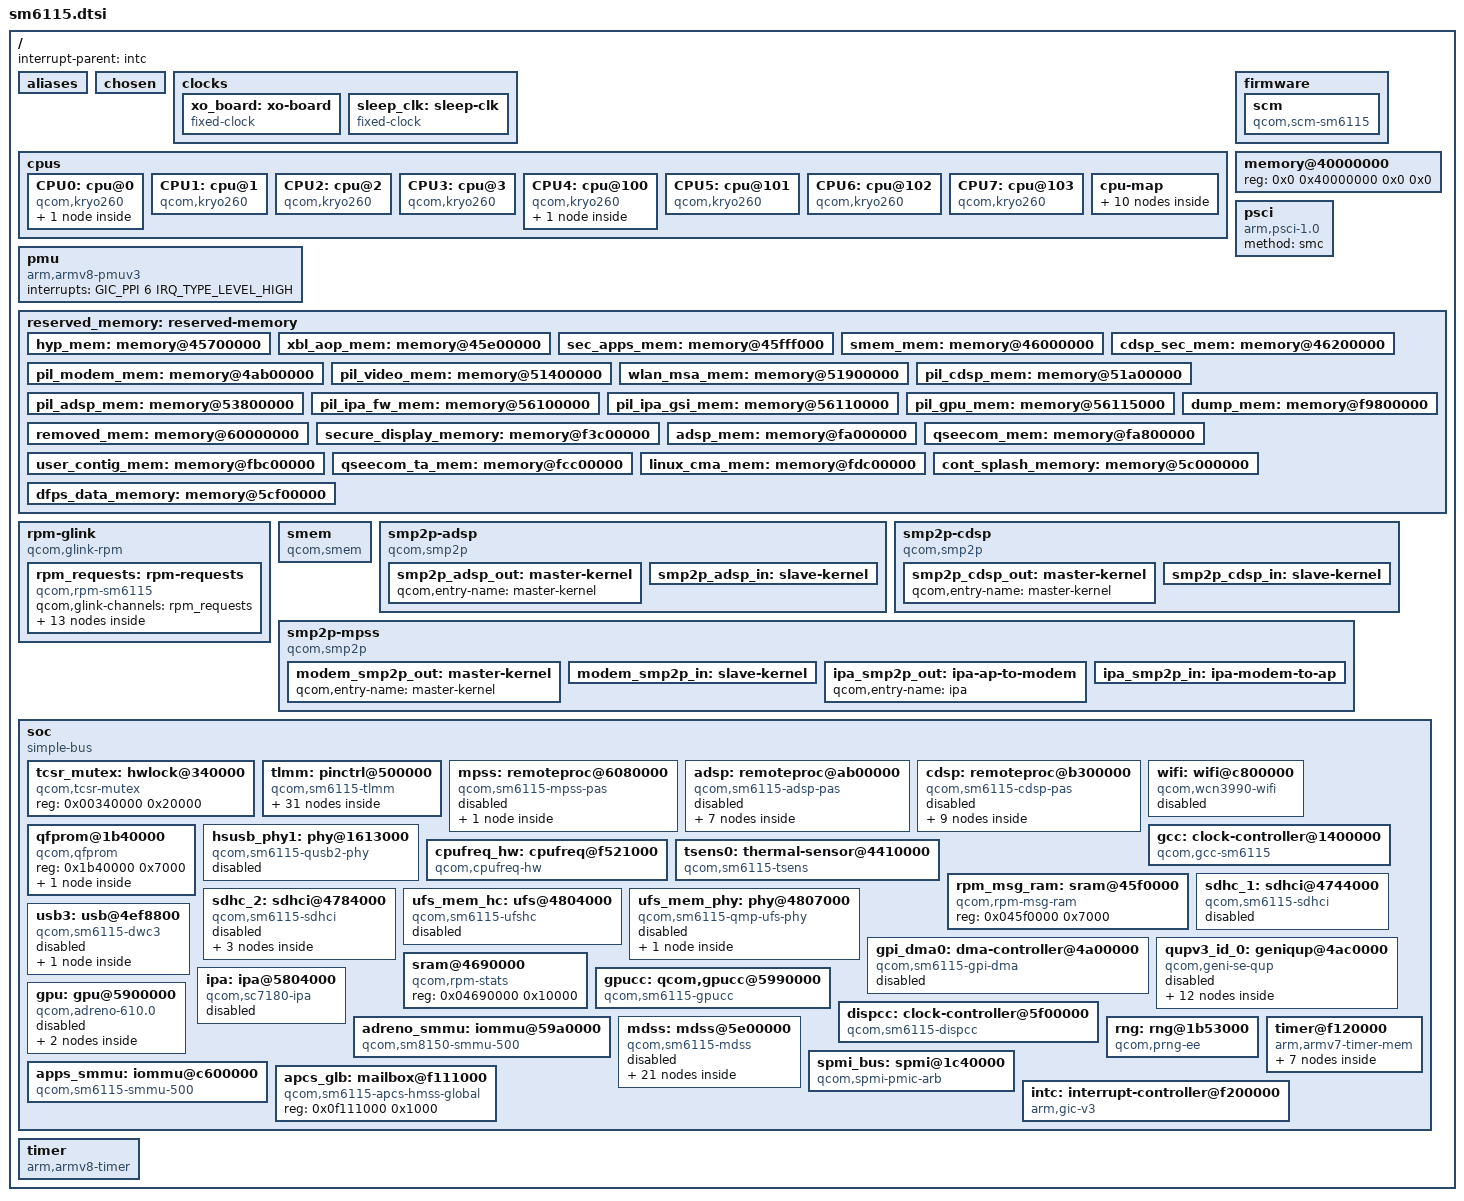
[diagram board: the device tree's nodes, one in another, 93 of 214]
// SPDX-License-Identifier: BSD-3-Clause

#include <dt-bindings/clock/qcom,gcc-sm6115.h>
#include <dt-bindings/clock/qcom,dispcc-sm6115.h>
#include <dt-bindings/clock/qcom,gpucc-sm6115.h>
#include <dt-bindings/clock/qcom,rpmcc.h>
#include <dt-bindings/gpio/gpio.h>
#include <dt-bindings/interrupt-controller/arm-gic.h>
#include <dt-bindings/power/qcom-rpmpd.h>

/ {
	interrupt-parent = <&intc>;
	#address-cells = <2>;
	#size-cells = <2>;
	
	aliases {
		
		mmc0 = &sdhc_1;
		mmc1 = &sdhc_2;
	};
	
	chosen {
		#address-cells = <2>;
		#size-cells = <2>;
		ranges;
		
	 };

	clocks {
		xo_board: xo-board {
			compatible = "fixed-clock";
			#clock-cells = <0>;
			clock-frequency = <19200000>;
			clock-output-names = "xo_board";
		};

		sleep_clk: sleep-clk {
			compatible = "fixed-clock";
			#clock-cells = <0>;
			clock-frequency = <32764>;
			clock-output-names = "sleep_clk";
		};
	};

	cpus {
		#address-cells = <2>;
		#size-cells = <0>;

		CPU0: cpu@0 {
			device_type = "cpu";
			compatible = "qcom,kryo260";
			reg = <0x0 0x0>;
			enable-method = "psci";
			capacity-dmips-mhz = <1024>;
			next-level-cache = <&L2_0>;
			qcom,freq-domain = <&cpufreq_hw 0>;
			L2_0: l2-cache {
				compatible = "cache";
			};
		};

		CPU1: cpu@1 {
			device_type = "cpu";
			compatible = "qcom,kryo260";
			reg = <0x0 0x1>;
			enable-method = "psci";
			capacity-dmips-mhz = <1024>;
			next-level-cache = <&L2_0>;
			qcom,freq-domain = <&cpufreq_hw 0>;
		};

		CPU2: cpu@2 {
			device_type = "cpu";
			compatible = "qcom,kryo260";
			reg = <0x0 0x2>;
			enable-method = "psci";
			capacity-dmips-mhz = <1024>;
			next-level-cache = <&L2_0>;
			qcom,freq-domain = <&cpufreq_hw 0>;
		};

		CPU3: cpu@3 {
			device_type = "cpu";
			compatible = "qcom,kryo260";
			reg = <0x0 0x3>;
			enable-method = "psci";
			capacity-dmips-mhz = <1024>;
			next-level-cache = <&L2_0>;
			qcom,freq-domain = <&cpufreq_hw 0>;
		};

		CPU4: cpu@100 {
			device_type = "cpu";
			compatible = "qcom,kryo260";
			reg = <0x0 0x100>;
			enable-method = "psci";
			capacity-dmips-mhz = <1638>;
			next-level-cache = <&L2_1>;
			qcom,freq-domain = <&cpufreq_hw 1>;
			L2_1: l2-cache {
				compatible = "cache";
			};
		};

		CPU5: cpu@101 {
			device_type = "cpu";
			compatible = "qcom,kryo260";
			reg = <0x0 0x101>;
			enable-method = "psci";
			capacity-dmips-mhz = <1638>;
			next-level-cache = <&L2_1>;
			qcom,freq-domain = <&cpufreq_hw 1>;
		};

		CPU6: cpu@102 {
			device_type = "cpu";
			compatible = "qcom,kryo260";
			reg = <0x0 0x102>;
			enable-method = "psci";
			capacity-dmips-mhz = <1638>;
			next-level-cache = <&L2_1>;
			qcom,freq-domain = <&cpufreq_hw 1>;
		};

		CPU7: cpu@103 {
			device_type = "cpu";
			compatible = "qcom,kryo260";
			reg = <0x0 0x103>;
			enable-method = "psci";
			capacity-dmips-mhz = <1638>;
			next-level-cache = <&L2_1>;
			qcom,freq-domain = <&cpufreq_hw 1>;
		};

		cpu-map {
			cluster0 {
				core0 {
					cpu = <&CPU0>;
				};

				core1 {
					cpu = <&CPU1>;
				};

				core2 {
					cpu = <&CPU2>;
				};

				core3 {
					cpu = <&CPU3>;
				};
			};

			cluster1 {
				core0 {
					cpu = <&CPU4>;
				};

				core1 {
					cpu = <&CPU5>;
				};

				core2 {
					cpu = <&CPU6>;
				};

				core3 {
					cpu = <&CPU7>;
				};
			};
		};
	};

	firmware {
		scm: scm {
			compatible = "qcom,scm-sm6115", "qcom,scm";
			#reset-cells = <1>;
		};
	};

	memory@40000000 {
		/* We expect the bootloader to fill in the size */
		reg = <0x0 0x40000000 0x0 0x0>;
		device_type = "memory";
	};

	pmu {
		compatible = "arm,armv8-pmuv3";
		interrupts = <GIC_PPI 6 IRQ_TYPE_LEVEL_HIGH>;
	};

	psci {
		compatible = "arm,psci-1.0";
		method = "smc";
	};

	reserved_memory: reserved-memory {
		#address-cells = <2>;
		#size-cells = <2>;
		ranges;

		hyp_mem: memory@45700000 {
			reg = <0x0 0x45700000 0x0 0x600000>;
			no-map;
		};

		xbl_aop_mem: memory@45e00000 {
			reg = <0x0 0x45e00000 0x0 0x140000>;
			no-map;
		};

		sec_apps_mem: memory@45fff000 {
			reg = <0x0 0x45fff000 0x0 0x1000>;
			no-map;
		};

		smem_mem: memory@46000000 {
			reg = <0x0 0x46000000 0x0 0x200000>;
			no-map;
		};

		cdsp_sec_mem: memory@46200000 {
			reg = <0x0 0x46200000 0x0 0x1e00000>;
			no-map;
		};

		pil_modem_mem: memory@4ab00000 {
			reg = <0x0 0x4ab00000 0x0 0x6900000>;
			no-map;
		};

		pil_video_mem: memory@51400000 {
			reg = <0x0 0x51400000 0x0 0x500000>;
			no-map;
		};

		wlan_msa_mem: memory@51900000 {
			reg = <0x0 0x51900000 0x0 0x100000>;
			no-map;
		};

		pil_cdsp_mem: memory@51a00000 {
			reg = <0x0 0x51a00000 0x0 0x1e00000>;
			no-map;
		};

		pil_adsp_mem: memory@53800000 {
			reg = <0x0 0x53800000 0x0 0x2800000>;
			no-map;
		};

		pil_ipa_fw_mem: memory@56100000 {
			reg = <0x0 0x56100000 0x0 0x10000>;
			no-map;
		};

		pil_ipa_gsi_mem: memory@56110000 {
			reg = <0x0 0x56110000 0x0 0x5000>;
			no-map;
		};

		pil_gpu_mem: memory@56115000 {
			reg = <0x0 0x56115000 0x0 0x2000>;
			no-map;
		};

		removed_mem: memory@60000000 {
			reg = <0x0 0x60000000 0x0 0x3900000>;
			no-map;
		};

		secure_display_memory: memory@f3c00000 {
			reg = <0x0 0xf3c00000 0x0 0x5c00000>;
			no-map;
		};

		dump_mem: memory@f9800000 {
			reg = <0x0 0xf9800000 0x0 0x800000>;
			no-map;
		};

		adsp_mem: memory@fa000000 {
			reg = <0x0 0xfa000000 0x0 0x800000>;
			no-map;
		};

		qseecom_mem: memory@fa800000 {
			reg = <0x0 0xfa800000 0x0 0x1400000>;
			no-map;
		};

		user_contig_mem: memory@fbc00000 {
			reg = <0x0 0xfbc00000 0x0 0x1000000>;
			no-map;
		};

		qseecom_ta_mem: memory@fcc00000 {
			reg = <0x0 0xfcc00000 0x0 0x1000000>;
			no-map;
		};

		linux_cma_mem: memory@fdc00000 {
			reg = <0x0 0xfdc00000 0x0 0x2000000>;
			no-map;
		};

		cont_splash_memory: memory@5c000000 {
			reg = <0x0 0x5c000000 0x0 0x00f00000>;
			no-map;
		};

		dfps_data_memory: memory@5cf00000 {
			reg = <0x0 0x5cf00000 0x0 0x0100000>;
			no-map;
		};

	};

	rpm-glink {
		compatible = "qcom,glink-rpm";

		interrupts = <GIC_SPI 194 IRQ_TYPE_EDGE_RISING>;
		qcom,rpm-msg-ram = <&rpm_msg_ram>;
		mboxes = <&apcs_glb 0>;

		rpm_requests: rpm-requests {
			compatible = "qcom,rpm-sm6115";
			qcom,glink-channels = "rpm_requests";

			rpmcc: clock-controller {
				compatible = "qcom,rpmcc-sm6115", "qcom,rpmcc";
				#clock-cells = <1>;
			};

			rpmpd: power-controller {
				compatible = "qcom,sm6115-rpmpd";
				#power-domain-cells = <1>;
				operating-points-v2 = <&rpmpd_opp_table>;

				rpmpd_opp_table: opp-table {
					compatible = "operating-points-v2";

					rpmpd_opp_ret: opp1 {
						opp-level = <RPM_SMD_LEVEL_RETENTION>;
					};

					rpmpd_opp_ret_plus: opp2 {
						opp-level = <RPM_SMD_LEVEL_RETENTION_PLUS>;
					};

					rpmpd_opp_min_svs: opp3 {
						opp-level = <RPM_SMD_LEVEL_MIN_SVS>;
					};

					rpmpd_opp_low_svs: opp4 {
						opp-level = <RPM_SMD_LEVEL_LOW_SVS>;
					};

					rpmpd_opp_svs: opp5 {
						opp-level = <RPM_SMD_LEVEL_SVS>;
					};

					rpmpd_opp_svs_plus: opp6 {
						opp-level = <RPM_SMD_LEVEL_SVS_PLUS>;
					};

					rpmpd_opp_nom: opp7 {
						opp-level = <RPM_SMD_LEVEL_NOM>;
					};

					rpmpd_opp_nom_plus: opp8 {
						opp-level = <RPM_SMD_LEVEL_NOM_PLUS>;
					};

					rpmpd_opp_turbo: opp9 {
						opp-level = <RPM_SMD_LEVEL_TURBO>;
					};

					rpmpd_opp_turbo_no_cpr: opp10 {
						opp-level = <RPM_SMD_LEVEL_TURBO_NO_CPR>;
					};
				};
			};
		};
	};

	smem: smem {
		compatible = "qcom,smem";
		memory-region = <&smem_mem>;
		hwlocks = <&tcsr_mutex 3>;
	};

	smp2p-adsp {
		compatible = "qcom,smp2p";
		qcom,smem = <443>, <429>;
		interrupts = <GIC_SPI 279 IRQ_TYPE_EDGE_RISING>;
		
		mboxes = <&apcs_glb 10>;

		qcom,local-pid = <0>;
		qcom,remote-pid = <2>;

		smp2p_adsp_out: master-kernel {
			qcom,entry-name = "master-kernel";
			#qcom,smem-state-cells = <1>;
		};

		smp2p_adsp_in: slave-kernel {
			qcom,entry-name = "slave-kernel";
			interrupt-controller;
			#interrupt-cells = <2>;
		};
	};
	
	smp2p-cdsp {
		compatible = "qcom,smp2p";
		qcom,smem = <94>, <432>;
		interrupts = <GIC_SPI 263 IRQ_TYPE_EDGE_RISING>;
		mboxes = <&apcs_glb 30>;

		qcom,local-pid = <0>;
		qcom,remote-pid = <5>;

		smp2p_cdsp_out: master-kernel {
			qcom,entry-name = "master-kernel";
			#qcom,smem-state-cells = <1>;
		};

		smp2p_cdsp_in: slave-kernel {
			qcom,entry-name = "slave-kernel";
			interrupt-controller;
			#interrupt-cells = <2>;
		};
	};
	
	smp2p-mpss {
		compatible = "qcom,smp2p";
		qcom,smem = <435>, <428>;

		interrupts = <GIC_SPI 70 IRQ_TYPE_EDGE_RISING>;
		mboxes = <&apcs_glb 14>;

		qcom,local-pid = <0>;
		qcom,remote-pid = <1>;

		modem_smp2p_out: master-kernel {
			qcom,entry-name = "master-kernel";
			#qcom,smem-state-cells = <1>;
		};

		modem_smp2p_in: slave-kernel {
			qcom,entry-name = "slave-kernel";

			interrupt-controller;
			#interrupt-cells = <2>;
		};
		
		ipa_smp2p_out: ipa-ap-to-modem {
			qcom,entry-name = "ipa";
			#qcom,smem-state-cells = <1>;
		};

		ipa_smp2p_in: ipa-modem-to-ap {
			qcom,entry-name = "ipa";
			interrupt-controller;
			#interrupt-cells = <2>;
		};
	};
	
	soc {
		#address-cells = <1>;
		#size-cells = <1>;
		ranges = <0 0 0 0xffffffff>;
		compatible = "simple-bus";

		tcsr_mutex: hwlock@340000 {
			compatible = "qcom,tcsr-mutex";
			reg = <0x00340000 0x20000>;
			#hwlock-cells = <1>;
		};

		tlmm: pinctrl@500000 {
			compatible = "qcom,sm6115-tlmm";
			reg = <0x00500000 0x400000>,
			      <0x00900000 0x400000>,
			      <0x00d00000 0x400000>;
			reg-names = "west", "south", "east";
			interrupts = <GIC_SPI 227 IRQ_TYPE_LEVEL_HIGH>;
			gpio-controller;
			gpio-ranges = <&tlmm 0 0 134>;
			#gpio-cells = <2>;
			interrupt-controller;
			#interrupt-cells = <2>;
			
			qup_i2c0_default: qup-i2c0-default {
				pins = "gpio0", "gpio1";
				function = "qup0";
				drive-strength = <2>;
				bias-pull-up;
			};

			qup_i2c1_default: qup-i2c1-default {
				pins = "gpio4", "gpio5";
				function = "qup1";
				drive-strength = <2>;
				bias-pull-up;
			};
			
			qup_i2c2_default: qup-i2c2-default {
				pins = "gpio6", "gpio7";
				function = "qup2";
				drive-strength = <2>;
				bias-pull-up;
			};

			qup_i2c3_default: qup-i2c3-default {
				pins = "gpio8", "gpio9";
				function = "qup3";
				drive-strength = <2>;
				bias-pull-up;
			};

			qup_i2c4_default: qup-i2c4-default {
				pins = "gpio12", "gpio13";
				function = "qup4";
				drive-strength = <2>;
				bias-pull-up;
			};

			qup_i2c5_default: qup-i2c5-default {
				pins = "gpio14", "gpio15";
				function = "qup5";
				drive-strength = <2>;
				bias-pull-up;
			};
			
			qup_spi0_default: qup-spi0-default {
				pins = "gpio0", "gpio1","gpio2", "gpio3";
				function = "qup0";
				drive-strength = <2>;
				bias-pull-up;
			};

			qup_spi1_default: qup-spi1-default {
				pins = "gpio4", "gpio5", "gpio69", "gpio70";
				function = "qup1";
				drive-strength = <2>;
				bias-pull-up;
			};
			
			qup_spi2_default: qup-spi2-default {
				pins = "gpio6", "gpio7", "gpio71", "gpio80";
				function = "qup2";
				drive-strength = <2>;
				bias-pull-up;
			};

			qup_spi3_default: qup-spi3-default {
				pins = "gpio8", "gpio9", "gpio10", "gpio11";
				function = "qup3";
				drive-strength = <2>;
				bias-pull-up;
			};

			qup_spi4_default: qup-spi4-default {
				pins = "gpio12", "gpio13", "gpio96", "gpio97";
				function = "qup4";
				drive-strength = <2>;
				bias-pull-up;
			};

			qup_spi5_default: qup-spi5-default {
				pins = "gpio14", "gpio15", "gpio16", "gpio17";
				function = "qup5";
				drive-strength = <2>;
				bias-pull-up;
			};
			
			sdc1_state_on: sdc1-on {
				clk {
					pins = "sdc1_clk";
					bias-disable;		/* NO pull */
					drive-strength = <16>;	/* 16 MA */
				};

				cmd {
					pins = "sdc1_cmd";
					bias-pull-up;		/* pull up */
					drive-strength = <10>;	/* 10 MA */
				};

				data {
					pins = "sdc1_data";
					bias-pull-up;		/* pull up */
					drive-strength = <10>;	/* 10 MA */
				};

				rclk {
					pins = "sdc1_rclk";
					bias-pull-down; /* pull down */
				};
			};

			sdc1_state_off: sdc1-off {
				clk {
					pins = "sdc1_clk";
					bias-disable;		/* NO pull */
					drive-strength = <2>;	/* 2 MA */
				};

				cmd {
					pins = "sdc1_cmd";
					bias-pull-up;		/* pull up */
					drive-strength = <2>;	/* 2 MA */
				};

				data {
					pins = "sdc1_data";
					bias-pull-up;		/* pull up */
					drive-strength = <2>;	/* 2 MA */
				};

				rclk {
					pins = "sdc1_rclk";
					bias-pull-down; /* pull down */
				};
			};

			sdc2_state_on: sdc2-on {
				clk {
					pins = "sdc2_clk";
					bias-disable;
					drive-strength = <16>;
				};

				cmd {
					pins = "sdc2_cmd";
					bias-pull-up;
					drive-strength = <10>;
				};

				data {
					pins = "sdc2_data";
					bias-pull-up;
					drive-strength = <10>;
				};

				sd-cd {
					pins = "gpio88";
					function = "gpio";
					bias-pull-up;
					drive-strength = <2>;
				};
			};

			
			sdc2_state_off: sdc2-off {
				clk {
					pins = "sdc2_clk";
					bias-disable;
					drive-strength = <2>;
				};

				cmd {
					pins = "sdc2_cmd";
					bias-pull-up;
					drive-strength = <2>;
				};

				data {
					pins = "sdc2_data";
					bias-pull-up;
					drive-strength = <2>;
				};
			};
		};
		
		mpss: remoteproc@6080000 {
			compatible = "qcom,sm6115-mpss-pas";
			reg = <0x06080000 0x100>;
			//verify type of interrupt
			interrupts-extended = <&intc GIC_SPI 307 IRQ_TYPE_EDGE_RISING>,
					      <&modem_smp2p_in 0 IRQ_TYPE_EDGE_RISING>,
					      <&modem_smp2p_in 1 IRQ_TYPE_EDGE_RISING>,
					      <&modem_smp2p_in 2 IRQ_TYPE_EDGE_RISING>,
					      <&modem_smp2p_in 3 IRQ_TYPE_EDGE_RISING>,
					      <&modem_smp2p_in 7 IRQ_TYPE_EDGE_RISING>;
			interrupt-names = "wdog", "fatal", "ready", "handover",
					  "stop-ack", "shutdown-ack";

			clocks = <&rpmcc RPM_SMD_XO_CLK_SRC>;
			clock-names = "xo";

			power-domains = <&rpmpd SM6115_VDDCX>;
			power-domain-names = "cx";

			memory-region = <&pil_modem_mem>;

			qcom,smem-states = <&modem_smp2p_out 0>;
			qcom,smem-state-names = "stop";

			status = "disabled";

			glink-edge {
				interrupts = <GIC_SPI 68 IRQ_TYPE_EDGE_RISING>;
				mboxes = <&apcs_glb 12>;
				label = "modem";
				qcom,remote-pid = <1>;
			};
		};
		
		adsp: remoteproc@ab00000 {
			compatible = "qcom,sm6115-adsp-pas";
			reg = <0xab00000 0x100>;
			//verigy interrupts
			interrupts-extended = <&intc GIC_SPI 282 IRQ_TYPE_LEVEL_HIGH>,
					      <&smp2p_adsp_in 0 IRQ_TYPE_EDGE_RISING>,
					      <&smp2p_adsp_in 1 IRQ_TYPE_EDGE_RISING>,
					      <&smp2p_adsp_in 2 IRQ_TYPE_EDGE_RISING>,
					      <&smp2p_adsp_in 3 IRQ_TYPE_EDGE_RISING>;
			interrupt-names = "wdog", "fatal", "ready",
					  "handover", "stop-ack";

			clocks = <&rpmcc RPM_SMD_XO_CLK_SRC>;
			clock-names = "xo";

			power-domains = <&rpmpd SM6115_VDD_LPI_CX>,
					<&rpmpd SM6115_VDD_LPI_MX>;
			power-domain-names = "lpi_cx", "lpi_mx";

			memory-region = <&pil_adsp_mem>;

			qcom,smem-states = <&smp2p_adsp_out 0>;
			qcom,smem-state-names = "stop";

			status = "disabled";

			glink-edge {
				interrupts = <GIC_SPI 277 IRQ_TYPE_EDGE_RISING>;
				
				mboxes = <&apcs_glb 8>;

				label = "lpass";
				qcom,remote-pid = <2>;

				fastrpc {
					compatible = "qcom,fastrpc";
					qcom,glink-channels = "fastrpcglink-apps-dsp";
					label = "adsp";
					#address-cells = <1>;
					#size-cells = <0>;

					compute-cb@3 {
						compatible = "qcom,fastrpc-compute-cb";
						reg = <3>;
						iommus = <&apps_smmu 0x01c3 0x0>;
					};

					compute-cb@4 {
						compatible = "qcom,fastrpc-compute-cb";
						reg = <4>;
						iommus = <&apps_smmu 0x01c4 0x0>;
					};

					compute-cb@5 {
						compatible = "qcom,fastrpc-compute-cb";
						reg = <5>;
						iommus = <&apps_smmu 0x01c5 0x0>;
						qcom,nsessions = <5>;
					};
					
					compute-cb@6 {
						compatible = "qcom,fastrpc-compute-cb";
						reg = <6>;
						iommus = <&apps_smmu 0x01c6 0x0>;
						qcom,nsessions = <6>;
					};
					
					compute-cb@7 {
						compatible = "qcom,fastrpc-compute-cb";
						reg = <7>;
						iommus = <&apps_smmu 0x01c7 0x0>;
						qcom,nsessions = <7>;
					};
				};
			};
		};
		
		cdsp: remoteproc@b300000 {
			compatible = "qcom,sm6115-cdsp-pas";
			reg = <0 0x0b300000 0 0x10000>;

			interrupts-extended = <&intc GIC_SPI 265 IRQ_TYPE_LEVEL_HIGH>,
					      <&smp2p_cdsp_in 0 IRQ_TYPE_EDGE_RISING>,
					      <&smp2p_cdsp_in 1 IRQ_TYPE_EDGE_RISING>,
					      <&smp2p_cdsp_in 2 IRQ_TYPE_EDGE_RISING>,
					      <&smp2p_cdsp_in 3 IRQ_TYPE_EDGE_RISING>;
			interrupt-names = "wdog", "fatal", "ready",
					  "handover", "stop-ack";

			clocks = <&rpmcc RPM_SMD_XO_CLK_SRC>;
			clock-names = "xo";

			power-domains = <&rpmpd SM6115_VDDCX>;
			power-domain-names = "cx";

			memory-region = <&pil_cdsp_mem>;

			qcom,smem-states = <&smp2p_cdsp_out 0>;
			qcom,smem-state-names = "stop";

			status = "disabled";

			glink-edge {
				interrupts = <GIC_SPI 261 IRQ_TYPE_EDGE_RISING>;
				
				mboxes = <&apcs_glb 28>;

				label = "cdsp";
				qcom,remote-pid = <5>;

				fastrpc {
					compatible = "qcom,fastrpc";
					qcom,glink-channels = "fastrpcglink-apps-dsp";
					label = "cdsp";
					#address-cells = <1>;
					#size-cells = <0>;

					compute-cb@1 {
						compatible = "qcom,fastrpc-compute-cb";
						reg = <1>;
						iommus = <&apps_smmu 0x0c01 0x20>;
					};

					compute-cb@2 {
						compatible = "qcom,fastrpc-compute-cb";
						reg = <2>;
						iommus = <&apps_smmu 0x0c02 0x20>;
					};

					compute-cb@3 {
						compatible = "qcom,fastrpc-compute-cb";
						reg = <3>;
						iommus = <&apps_smmu 0x0c03 0x20>;
					};

					compute-cb@4 {
						compatible = "qcom,fastrpc-compute-cb";
						reg = <4>;
						iommus = <&apps_smmu 0x0c04 0x20>;
					};

					compute-cb@5 {
						compatible = "qcom,fastrpc-compute-cb";
						reg = <5>;
						iommus = <&apps_smmu 0x0c05 0x20>;
					};

					compute-cb@6 {
						compatible = "qcom,fastrpc-compute-cb";
						reg = <6>;
						iommus = <&apps_smmu 0x0c06 0x20>;
					};

					compute-cb@8 {
						compatible = "qcom,fastrpc-compute-cb";
						reg = <8>;
						iommus = <&apps_smmu 0x0c08 0x20>;
					};

					/* note: secure cb9 in downstream */
				};
			};
		};
		
		wifi: wifi@c800000{
			compatible = "qcom,wcn3990-wifi";
			reg = <0 0xc800000 0 0x800000>;
			reg-names = "membase";
			memory-region = <&wlan_msa_mem>;
			interrupts = <GIC_SPI 358 IRQ_TYPE_LEVEL_HIGH>,
				     <GIC_SPI 359 IRQ_TYPE_LEVEL_HIGH>,
				     <GIC_SPI 360 IRQ_TYPE_LEVEL_HIGH>,
				     <GIC_SPI 361 IRQ_TYPE_LEVEL_HIGH>,
				     <GIC_SPI 362 IRQ_TYPE_LEVEL_HIGH>,
				     <GIC_SPI 363 IRQ_TYPE_LEVEL_HIGH>,
				     <GIC_SPI 364 IRQ_TYPE_LEVEL_HIGH>,
				     <GIC_SPI 365 IRQ_TYPE_LEVEL_HIGH>,
				     <GIC_SPI 366 IRQ_TYPE_LEVEL_HIGH>,
				     <GIC_SPI 367 IRQ_TYPE_LEVEL_HIGH>,
				     <GIC_SPI 368 IRQ_TYPE_LEVEL_HIGH>,
				     <GIC_SPI 369 IRQ_TYPE_LEVEL_HIGH>;
			iommus = <&apps_smmu 0x1a0 0x1>;
			qcom,msa-fixed-perm;
			status = "disabled";
		};
		
		qfprom@1b40000 {
			compatible = "qcom,qfprom";
			reg = <0x1b40000 0x7000>;
			#address-cells = <1>;
			#size-cells = <1>;

			qusb2_hstx_trim: hstx_trim@25b {
				// reg = <0x258 0x4>;
				// bits = <0x19 4>;
				reg = <0x25b 0x1>;
				bits = <1 4>;
			};
		};

		gcc: clock-controller@1400000 {
			compatible = "qcom,gcc-sm6115";
			reg = <0x01400000 0x1f0000>;
			#clock-cells = <1>;
			#reset-cells = <1>;
			#power-domain-cells = <1>;
			clock-names = "bi_tcxo", "sleep_clk";
			clocks = <&rpmcc RPM_SMD_XO_CLK_SRC>, <&sleep_clk>;
		};

		hsusb_phy1: phy@1613000 {
			compatible = "qcom,sm6115-qusb2-phy";
			reg = <0x01613000 0x180>;
			#phy-cells = <0>;

			clocks = <&rpmcc RPM_SMD_XO_CLK_SRC>,
				 <&gcc GCC_AHB2PHY_USB_CLK>;
			clock-names = "ref", "cfg_ahb";

			resets = <&gcc GCC_QUSB2PHY_PRIM_BCR>;
			status = "disabled";
		};
		
		cpufreq_hw: cpufreq@f521000 {
			compatible = "qcom,cpufreq-hw";
			reg = <0xf521000 0x1000>, <0xf523000 0x1000>;
			
			reg-names = "freq-domain0", "freq-domain1";
			clocks = <&rpmcc RPM_SMD_XO_CLK_SRC>, <&gcc GPLL0>;
			clock-names = "xo", "alternate";

			#freq-domain-cells = <1>;
		};
		
		tsens0: thermal-sensor@4410000 {
			compatible = "qcom,sm6115-tsens", "qcom,tsens-v2";
			reg = <0x04411000 0x1ff>, /* TM */
			      <0x04410000 0x8>; /* SROT */
			#qcom,sensors = <16>;
			interrupts = <GIC_SPI 275 IRQ_TYPE_LEVEL_HIGH>,
				     <GIC_SPI 190 IRQ_TYPE_LEVEL_HIGH>;
			interrupt-names = "uplow", "critical";
			#thermal-sensor-cells = <1>;
		};

		rpm_msg_ram: sram@45f0000 {
			compatible = "qcom,rpm-msg-ram";
			reg = <0x045f0000 0x7000>;
		};

		sdhc_1: sdhci@4744000 {
			compatible = "qcom,sm6115-sdhci", "qcom,sdhci-msm-v5";
			reg = <0x04744000 0x1000>, <0x04745000 0x1000>;
			reg-names = "hc", "core";

			interrupts = <GIC_SPI 348 IRQ_TYPE_LEVEL_HIGH>,
				     <GIC_SPI 352 IRQ_TYPE_LEVEL_HIGH>;
			interrupt-names = "hc_irq", "pwr_irq";

			clocks = <&gcc GCC_SDCC1_AHB_CLK>,
				 <&gcc GCC_SDCC1_APPS_CLK>,
				 <&xo_board>;
			clock-names = "iface", "core", "xo";

			power-domains = <&rpmpd SM6115_VDDCX>;

			bus-width = <8>;
			non-removable;
			status = "disabled";
		};

		sdhc_2: sdhci@4784000 {
			compatible = "qcom,sm6115-sdhci", "qcom,sdhci-msm-v5";
			reg = <0x04784000 0x1000>;
			reg-names = "hc";

			interrupts = <GIC_SPI 350 IRQ_TYPE_LEVEL_HIGH>,
				     <GIC_SPI 353 IRQ_TYPE_LEVEL_HIGH>;
			interrupt-names = "hc_irq", "pwr_irq";

			clocks = <&gcc GCC_SDCC2_AHB_CLK>,
				 <&gcc GCC_SDCC2_APPS_CLK>,
				 <&xo_board>;
			clock-names = "iface", "core", "xo";
			qcom,dll-config = <0x0007642c>;
			qcom,ddr-config = <0x80040868>;
			pinctrl-0 = <&sdc2_state_on>;
			pinctrl-1 = <&sdc2_state_off>;
			pinctrl-names = "default", "sleep";

			power-domains = <&rpmpd SM6115_VDDCX>;
			operating-points-v2 = <&sdhc2_opp_table>;
			iommus = <&apps_smmu 0x00a0 0x0>;
			resets = <&gcc GCC_SDCC2_BCR>;
			bus-width = <4>;
			status = "disabled";
			
			sdhc2_opp_table: sdhc2-opp-table {
				compatible = "operating-points-v2";

				opp-100000000 {
					opp-hz = /bits/ 64 <100000000>;
					required-opps = <&rpmpd_opp_low_svs>;
				};

				opp-202000000 {
					opp-hz = /bits/ 64 <202000000>;
					required-opps = <&rpmpd_opp_nom>;
				};
			};
		};
		
		ufs_mem_hc: ufs@4804000 {
			compatible = "qcom,sm6115-ufshc", "qcom,ufshc",
				     "jedec,ufs-2.0";
			reg = <0x4804000  0x3000>,
			      <0x4810000 0x8000>;
			reg-names = "std", "ice";
			interrupts = <GIC_SPI 356 IRQ_TYPE_LEVEL_HIGH>;
			phys = <&ufs_mem_phy_lanes>;
			phy-names = "ufsphy";
			lanes-per-direction = <1>;
			#reset-cells = <1>;
			resets = <&gcc GCC_UFS_PHY_BCR>;
			reset-names = "rst";

			power-domains = <&gcc GCC_UFS_PHY_GDSC>;

			iommus = <&apps_smmu 0x100 0x0>;

			clock-names = "core_clk",
				      "bus_aggr_clk",
				      "iface_clk",
				      "core_clk_unipro",
				      "ref_clk",
				      "tx_lane0_sync_clk",
				      "rx_lane0_sync_clk",
				      "ice_core_clk";
			clocks = <&gcc GCC_UFS_PHY_AXI_CLK>,
				 <&gcc GCC_SYS_NOC_UFS_PHY_AXI_CLK>, 
				 <&gcc GCC_UFS_PHY_AHB_CLK>,
				 <&gcc GCC_UFS_PHY_UNIPRO_CORE_CLK>,
				 <&xo_board>,
				 <&gcc GCC_UFS_PHY_TX_SYMBOL_0_CLK>,
				 <&gcc GCC_UFS_PHY_RX_SYMBOL_0_CLK>,
				 <&gcc GCC_UFS_PHY_ICE_CORE_CLK>;
			freq-table-hz =
				<50000000 200000000>,
				<0 0>,
				<0 0>,
				<37500000 150000000>,
				<75000000 300000000>,
				<0 0>,
				<0 0>,
				<0 0>;

			status = "disabled";
		};

		ufs_mem_phy: phy@4807000 {
			compatible = "qcom,sm6115-qmp-ufs-phy";
			reg = <0x4807000 0xdb8>;
			#address-cells = <1>;
			#size-cells = <1>;
			ranges;

			clock-names = "ref",
				      "ref_aux";
			clocks = <&gcc GCC_UFS_CLKREF_CLK>,
				 <&gcc GCC_UFS_PHY_PHY_AUX_CLK>;

			resets = <&ufs_mem_hc 0>;
			reset-names = "ufsphy";

			status = "disabled";

			ufs_mem_phy_lanes: lanes@4807400 {
				reg = <0x4807400 0x098>,
				      <0x4807600 0x130>,
				      <0x4807c00 0x16c>;
				#phy-cells = <0>;
			};

		};
		
		gpi_dma0: dma-controller@4a00000 {
			compatible = "qcom,sm6115-gpi-dma";
			reg = <0x4a00000 0x60000>;
			interrupts = <GIC_SPI 335 IRQ_TYPE_LEVEL_HIGH>,
				<GIC_SPI 336 IRQ_TYPE_LEVEL_HIGH>,
				<GIC_SPI 337 IRQ_TYPE_LEVEL_HIGH>,
				<GIC_SPI 338 IRQ_TYPE_LEVEL_HIGH>,
				<GIC_SPI 339 IRQ_TYPE_LEVEL_HIGH>,
				<GIC_SPI 340 IRQ_TYPE_LEVEL_HIGH>,
				<GIC_SPI 341 IRQ_TYPE_LEVEL_HIGH>,
				<GIC_SPI 342 IRQ_TYPE_LEVEL_HIGH>,
				<GIC_SPI 343 IRQ_TYPE_LEVEL_HIGH>,
				<GIC_SPI 344 IRQ_TYPE_LEVEL_HIGH>;
			dma-channels =  <10>;
			dma-channel-mask = <0xf>;
			iommus = <&apps_smmu 0xf6 0x0>;
			#dma-cells = <3>;
			status = "disabled";
	};
	
		qupv3_id_0: geniqup@4ac0000 {
			compatible = "qcom,geni-se-qup";
			reg = <0x4ac0000 0x2000>;
			clock-names = "m-ahb", "s-ahb";
			clocks = <&gcc GCC_QUPV3_WRAP_0_M_AHB_CLK>,
				 <&gcc GCC_QUPV3_WRAP_0_S_AHB_CLK>;
			#address-cells = <1>;
			#size-cells = <1>;
			iommus = <&apps_smmu 0xe3 0x0>;
			ranges;
			status = "disabled";
			
			i2c0: i2c@4a80000 {
				compatible = "qcom,geni-i2c";
				reg = <0x004a80000 0x4000>;
				clock-names = "se";
				clocks = <&gcc GCC_QUPV3_WRAP0_S0_CLK>;
				pinctrl-names = "default";
				pinctrl-0 = <&qup_i2c0_default>;
				interrupts = <GIC_SPI 327 IRQ_TYPE_LEVEL_HIGH>;
				#address-cells = <1>;
				#size-cells = <0>;
				status = "disabled";
			};
			spi0: spi@4a80000 {
				compatible = "qcom,geni-spi";
				reg = <0x004a80000 0x4000>;
				clock-names = "se";
				clocks = <&gcc GCC_QUPV3_WRAP0_S0_CLK>;
				pinctrl-names = "default";
				pinctrl-0 = <&qup_spi0_default>;
				interrupts = <GIC_SPI 327 IRQ_TYPE_LEVEL_HIGH>;
				#address-cells = <1>;
				#size-cells = <0>;
				status = "disabled";
			};
			
			i2c1: i2c@4a84000 {
				compatible = "qcom,geni-i2c";
				reg = <0x004a84000 0x4000>;
				clock-names = "se";
				clocks = <&gcc GCC_QUPV3_WRAP0_S1_CLK>;
				pinctrl-names = "default";
				pinctrl-0 = <&qup_i2c1_default>;
				interrupts = <GIC_SPI 328 IRQ_TYPE_LEVEL_HIGH>;
				#address-cells = <1>;
				#size-cells = <0>;
				status = "disabled";
			};
			
			spi1: spi@4a84000 {
				compatible = "qcom,geni-spi";
				reg = <0x004a84000 0x4000>;
				clock-names = "se";
				clocks = <&gcc GCC_QUPV3_WRAP0_S1_CLK>;
				pinctrl-names = "default";
				pinctrl-0 = <&qup_spi1_default>;
				interrupts = <GIC_SPI 328 IRQ_TYPE_LEVEL_HIGH>;
				#address-cells = <1>;
				#size-cells = <0>;
				status = "disabled";
			};
			
			i2c2: i2c@4a88000 {
				compatible = "qcom,geni-i2c";
				reg = <0x004a88000 0x4000>;
				clock-names = "se";
				clocks = <&gcc GCC_QUPV3_WRAP0_S2_CLK>;
				pinctrl-names = "default";
				pinctrl-0 = <&qup_i2c2_default>;
				interrupts = <GIC_SPI 329 IRQ_TYPE_LEVEL_HIGH>;
				#address-cells = <1>;
				#size-cells = <0>;
				status = "disabled";
			};
			
			spi2: spi@4a88000 {
				compatible = "qcom,geni-spi";
				reg = <0x004a88000 0x4000>;
				clock-names = "se";
				clocks = <&gcc GCC_QUPV3_WRAP0_S2_CLK>;
				pinctrl-names = "default";
				pinctrl-0 = <&qup_spi2_default>;
				interrupts = <GIC_SPI 329 IRQ_TYPE_LEVEL_HIGH>;
				#address-cells = <1>;
				#size-cells = <0>;
				status = "disabled";
			};
					
			i2c3: i2c@4a8c000 {
				compatible = "qcom,geni-i2c";
				reg = <0x004a8c000 0x4000>;
				clock-names = "se";
				clocks = <&gcc GCC_QUPV3_WRAP0_S3_CLK>;
				pinctrl-names = "default";
				pinctrl-0 = <&qup_i2c3_default>;
				interrupts = <GIC_SPI 330 IRQ_TYPE_LEVEL_HIGH>;
				#address-cells = <1>;
				#size-cells = <0>;
				status = "disabled";
			};
			
			spi3: spi@4a8c000 {
				compatible = "qcom,geni-spi";
				reg = <0x004a8c000 0x4000>;
				clock-names = "se";
				clocks = <&gcc GCC_QUPV3_WRAP0_S3_CLK>;
				pinctrl-names = "default";
				pinctrl-0 = <&qup_spi3_default>;
				interrupts = <GIC_SPI 330 IRQ_TYPE_LEVEL_HIGH>;
				#address-cells = <1>;
				#size-cells = <0>;
				status = "disabled";
			};
			i2c4: i2c@4a90000 {
				compatible = "qcom,geni-i2c";
				reg = <0x004a90000 0x4000>;
				clock-names = "se";
				clocks = <&gcc GCC_QUPV3_WRAP0_S4_CLK>;
				pinctrl-names = "default";
				pinctrl-0 = <&qup_i2c4_default>;
				interrupts = <GIC_SPI 331 IRQ_TYPE_LEVEL_HIGH>;
				#address-cells = <1>;
				#size-cells = <0>;
				status = "disabled";
			};
			
			spi4: spi@4a90000 {
				compatible = "qcom,geni-spi";
				reg = <0x004a90000 0x4000>;
				clock-names = "se";
				clocks = <&gcc GCC_QUPV3_WRAP0_S4_CLK>;
				pinctrl-names = "default";
				pinctrl-0 = <&qup_spi4_default>;
				interrupts = <GIC_SPI 331 IRQ_TYPE_LEVEL_HIGH>;
				#address-cells = <1>;
				#size-cells = <0>;
				status = "disabled";
			};
			
			i2c5: i2c@4a94000 {
				compatible = "qcom,geni-i2c";
				reg = <0x004a94000 0x4000>;
				clock-names = "se";
				clocks = <&gcc GCC_QUPV3_WRAP0_S5_CLK>;
				pinctrl-names = "default";
				pinctrl-0 = <&qup_i2c5_default>;
				interrupts = <GIC_SPI 332 IRQ_TYPE_LEVEL_HIGH>;
				#address-cells = <1>;
				#size-cells = <0>;
				status = "disabled";
			};
			
			spi5: spi@4a94000 {
				compatible = "qcom,geni-spi";
				reg = <0x004a94000 0x4000>;
				clock-names = "se";
				clocks = <&gcc GCC_QUPV3_WRAP0_S5_CLK>;
				pinctrl-names = "default";
				pinctrl-0 = <&qup_spi5_default>;
				interrupts = <GIC_SPI 332 IRQ_TYPE_LEVEL_HIGH>;
				#address-cells = <1>;
				#size-cells = <0>;
				status = "disabled";
			};
		};
		
		usb3: usb@4ef8800 {
			compatible = "qcom,sm6115-dwc3", "qcom,dwc3";
			reg = <0x04ef8800 0x400>;
			#address-cells = <1>;
			#size-cells = <1>;
			ranges;
			interrupts = <GIC_SPI 260 IRQ_TYPE_LEVEL_HIGH>,
				     <GIC_SPI 422 IRQ_TYPE_LEVEL_HIGH>;
			interrupt-names = "hs_phy_irq", "ss_phy_irq";

			clocks = <&gcc GCC_CFG_NOC_USB3_PRIM_AXI_CLK>,
				 <&gcc GCC_USB30_PRIM_MASTER_CLK>,
				 <&gcc GCC_SYS_NOC_USB3_PRIM_AXI_CLK>,
				 <&gcc GCC_USB30_PRIM_SLEEP_CLK>,
				 <&gcc GCC_USB30_PRIM_MOCK_UTMI_CLK>,
				 <&gcc GCC_USB3_PRIM_CLKREF_CLK>;
			clock-names = "cfg_noc",
				      "core",
				      "iface",
				      "sleep",
				      "mock_utmi",
				      "xo";

			assigned-clocks = <&gcc GCC_USB30_PRIM_MOCK_UTMI_CLK>,
					  <&gcc GCC_USB30_PRIM_MASTER_CLK>;
			assigned-clock-rates = <19200000>, <66666667>;

			power-domains = <&gcc GCC_USB30_PRIM_GDSC>;
			qcom,select-utmi-as-pipe-clk;
			status = "disabled";

			usb3_dwc3: usb@4e00000 {
				compatible = "snps,dwc3";
				reg = <0x04e00000 0xcd00>;
				interrupts = <GIC_SPI 255 IRQ_TYPE_LEVEL_HIGH>;
				phys = <&hsusb_phy1>;
				phy-names = "usb2-phy";
				snps,dis_u2_susphy_quirk;
				snps,dis_enblslpm_quirk;
				snps,has-lpm-erratum;
				snps,hird-threshold = /bits/ 8 <0x10>;
				snps,usb3_lpm_capable;
				maximum-speed = "high-speed";
				dr_mode = "peripheral";
				iommus = <&apps_smmu 0x120 0x0>;
			};
		};

		sram@4690000 {
			compatible = "qcom,rpm-stats";
			reg = <0x04690000 0x10000>;
		};
		
		ipa: ipa@5804000 {
			compatible = "qcom,sc7180-ipa";
			
			iommus = <&apps_smmu 0x140 0x0>,
				 <&apps_smmu 0x142 0x0>;
			reg = <0x5840000 0x34000>, 
			      <0x5847000 0 0x2000>,
			      <0x5804000 0x28000>;
			reg-names = "ipa-reg",
				    "ipa-shared",
				    "gsi";

			interrupts-extended = <&intc GIC_SPI 257 IRQ_TYPE_EDGE_RISING>,
					      <&intc GIC_SPI 259 IRQ_TYPE_LEVEL_HIGH>,
					      <&ipa_smp2p_in 0 IRQ_TYPE_EDGE_RISING>,
					      <&ipa_smp2p_in 1 IRQ_TYPE_EDGE_RISING>;
			interrupt-names = "ipa",
					  "gsi",
					  "ipa-clock-query",
					  "ipa-setup-ready";

			clocks = <&rpmcc RPM_SMD_IPA_CLK>;
			clock-names = "core";

			qcom,smem-states = <&ipa_smp2p_out 0>,
					   <&ipa_smp2p_out 1>;
			qcom,smem-state-names = "ipa-clock-enabled-valid",
						"ipa-clock-enabled";

			status = "disabled";
		};
		
		gpucc: qcom,gpucc@5990000 {
			compatible = "qcom,sm6115-gpucc";
			reg = <0x5990000 0x9000>;
			clocks = <&rpmcc RPM_SMD_XO_CLK_SRC>,
				 <&gcc GCC_GPU_GPLL0_CLK_SRC>,
				 <&gcc GCC_GPU_GPLL0_DIV_CLK_SRC>;
			clock-names = "bi_tcxo",
				      "gcc_gpu_gpll0_clk_src",
				      "gcc_gpu_gpll0_div_clk_src";
			#clock-cells = <1>;
			#reset-cells = <1>;
			#power-domain-cells = <1>;
	};
	
		dispcc: clock-controller@5f00000 {
			compatible = "qcom,sm6115-dispcc";
			reg = <0x5f00000 0x20000>;
          		  clocks = <&rpmcc RPM_SMD_XO_CLK_SRC>,
                  	   <&gcc GCC_DISP_GPLL0_CLK_SRC>,
                 	    <&gcc GCC_DISP_GPLL0_DIV_CLK_SRC>,
			<&dsi_phy0 0>,
			<&dsi_phy0 1>,
			<&sleep_clk>;
			
			clock-names = "bi_tcxo",
				 	"gcc_disp_gpll0_clk_src",
				 	 "gcc_disp_gpll0_div_clk_src",
				      "dsi0_phy_pll_out_byteclk",
				      "dsi0_phy_pll_out_dsiclk",
				      "sleep";
				     
			#clock-cells = <1>;
			#reset-cells = <1>;
			#power-domain-cells = <1>;
    };

		gpu: gpu@5900000 {
			compatible = "qcom,adreno-610.0", "qcom,adreno";
			reg = <0x05900000 0x90000>,
			      <0x05961000 0x800>;
			reg-names = "kgsl_3d0_reg_memory",
				    "cx_dbgc";
			interrupts = <GIC_SPI 177 IRQ_TYPE_LEVEL_HIGH>;
			
			iommus = <&adreno_smmu 0 1>;
			
			operating-points-v2 = <&gpu_opp_table>;

			#cooling-cells = <2>;
			
			clocks = <&gpucc GPU_CC_GX_GFX3D_CLK>,
			<&gpucc GPU_CC_CXO_CLK>,
			<&gcc GCC_BIMC_GPU_AXI_CLK>,
			<&gpucc GPU_CC_AHB_CLK>,
			<&gcc GCC_GPU_MEMNOC_GFX_CLK>,
			<&gpucc GPU_CC_CX_GMU_CLK>,
			<&gpucc GPU_CC_HLOS1_VOTE_GPU_SMMU_CLK>;
			clock-names = "core", "rbbmtimer", "mem",
				"iface", "mem_iface", "gmu",
				"smmu_vote";
			
			 power-domains = <&gpucc GPU_GX_GDSC>;
			 power-domain-names = "gx";
			 
			status = "disabled";
			gpu_opp_table: opp-table {
				compatible = "operating-points-v2";

				opp-320000000 {
					opp-hz = /bits/ 64 <320000000>;
					opp-level = <RPM_SMD_LEVEL_NOM>;
					//opp-level = <RPM_SMD_LEVEL_LOW_SVS>;
					//opp-supported-hw = <0xff>;
				};
/*
				opp-465000000 {
					opp-hz = /bits/ 64 <465000000>;
					opp-level = <RPM_SMD_LEVEL_SVS>;
				//	opp-supported-hw = <0xff>;
				};

				opp-600000000 {
					opp-hz = /bits/ 64 <600000000>;
					opp-level = <RPM_SMD_LEVEL_SVS_PLUS>;
				//	opp-supported-hw = <0xff>;
				};

				opp-745000000 {
					opp-hz = /bits/ 64 <745000000>;
					opp-level = <RPM_SMD_LEVEL_NOM>;
					//opp-supported-hw = <0xff>;
				};

				opp-820000000 {
					opp-hz = /bits/ 64 <820000000>;
					opp-level = <RPM_SMD_LEVEL_NOM_PLUS>;
					//opp-supported-hw = <0xff>;
				};

				opp-900000000 {
					opp-hz = /bits/ 64 <900000000>;
					opp-level = <RPM_SMD_LEVEL_TURBO>;
					//opp-supported-hw = <0xff>;
				};

				opp-980000000 {
					opp-hz = /bits/ 64 <980000000>;
					opp-level = <RPM_SMD_LEVEL_TURBO_NO_CPR>;
					//opp-supported-hw = <0xff>;
				};
				*/
			};
		};

		/* SMMU HLOS1 clock removed */
		adreno_smmu: iommu@59a0000 {
			compatible = "qcom,sm8150-smmu-500", "arm,mmu-500";
			reg = <0x59a0000 0x10000>;
			#iommu-cells = <2>;
			#global-interrupts = <1>;

			status = "okay";
			interrupts =	<GIC_SPI 163 IRQ_TYPE_LEVEL_HIGH>,
				<GIC_SPI 167 IRQ_TYPE_LEVEL_HIGH>,
				<GIC_SPI 168 IRQ_TYPE_LEVEL_HIGH>,
				<GIC_SPI 169 IRQ_TYPE_LEVEL_HIGH>,
				<GIC_SPI 170 IRQ_TYPE_LEVEL_HIGH>,
				<GIC_SPI 171 IRQ_TYPE_LEVEL_HIGH>,
				<GIC_SPI 172 IRQ_TYPE_LEVEL_HIGH>,
				<GIC_SPI 173 IRQ_TYPE_LEVEL_HIGH>,
				<GIC_SPI 174 IRQ_TYPE_LEVEL_HIGH>;
				
			clocks = <&gcc GCC_GPU_MEMNOC_GFX_CLK>,
				 <&gcc GCC_GPU_SNOC_DVM_GFX_CLK>,
				 <&gpucc GPU_CC_AHB_CLK>;
				
			 
			clock-names = "bus", "iface", "ahb";
			      
			      
			power-domains = <&gpucc GPU_CX_GDSC>;
		};

		mdss: mdss@5e00000 {
			compatible = "qcom,sm6115-mdss";
			reg = <0x05e00000 0x1000>;
			reg-names = "mdss";

			power-domains = <&dispcc MDSS_GDSC>;

			clocks = <&gcc GCC_DISP_AHB_CLK>,
				 <&gcc GCC_DISP_HF_AXI_CLK>,
				 <&dispcc DISP_CC_MDSS_MDP_CLK>;
			clock-names = "iface", "bus", "core";
			
			assigned-clocks = <&dispcc DISP_CC_MDSS_MDP_CLK>;
			assigned-clock-rates = <307200000>;

			interrupts = <GIC_SPI 186 IRQ_TYPE_LEVEL_HIGH>;
			interrupt-controller;
			#interrupt-cells = <1>;

			iommus = <&apps_smmu 0x420 0x2>,
             			 <&apps_smmu 0x421 0x0>;
			  

			#address-cells = <1>;
			#size-cells = <1>;
			ranges;

			status = "disabled";

			mdp: mdp@5e01000 {
				compatible = "qcom,sm6115-dpu";
				reg = <0x05e01000 0x8f000>,
				      <0x05eb0000 0x2008>;
				reg-names = "mdp", "vbif";

				clocks = <&gcc GCC_DISP_HF_AXI_CLK>,
					 <&dispcc DISP_CC_MDSS_AHB_CLK>,
					 <&dispcc DISP_CC_MDSS_ROT_CLK>,
					 <&dispcc DISP_CC_MDSS_MDP_LUT_CLK>,
					 <&dispcc DISP_CC_MDSS_MDP_CLK>,
					 <&dispcc DISP_CC_MDSS_VSYNC_CLK>;
				clock-names = "bus", "iface", "rot", "lut", "core",
					      "vsync";
				assigned-clocks = <&dispcc DISP_CC_MDSS_MDP_CLK>,
						  <&dispcc DISP_CC_MDSS_VSYNC_CLK>,
						  <&dispcc DISP_CC_MDSS_ROT_CLK>,
						  <&dispcc DISP_CC_MDSS_MDP_LUT_CLK>;
				assigned-clock-rates = <256000000>,
						       <19200000>,
						       <192000000>,
						       <192000000>;

				operating-points-v2 = <&mdp_opp_table>;
				power-domains = <&rpmpd SM6115_VDDCX>;

				interrupt-parent = <&mdss>;
				interrupts = <0>;

				status = "disabled";

				ports {
					#address-cells = <1>;
					#size-cells = <0>;

					port@0 {
						reg = <0>;
						dpu_intf1_out: endpoint {
							remote-endpoint = <&dsi0_in>;
						};
					};

				};

				mdp_opp_table: mdp-opp-table {
					compatible = "operating-points-v2";

					opp-19200000 {
						opp-hz = /bits/ 64 <19200000>;
						required-opps = <&rpmpd_opp_min_svs>;
					};

					opp-192000000 {
						opp-hz = /bits/ 64 <192000000>;
						required-opps = <&rpmpd_opp_low_svs>;
					};

					opp-256000000 {
						opp-hz = /bits/ 64 <256000000>;
						required-opps = <&rpmpd_opp_svs>;
					};

					opp-307200000 {
						opp-hz = /bits/ 64 <307200000>;
						required-opps = <&rpmpd_opp_svs_plus>;
					};
					
					opp-384000000 {
						opp-hz = /bits/ 64 <384000000>;
						required-opps = <&rpmpd_opp_nom>;
					};
				};

			};

			dsi0: dsi@5e94000 {
				compatible = "qcom,dsi-ctrl-6g-qcm2290";
				reg = <0x05e94000 0x400>;
				reg-names = "dsi_ctrl";

				interrupt-parent = <&mdss>;
				interrupts = <4>;

				clocks = <&dispcc DISP_CC_MDSS_BYTE0_CLK>,
					 <&dispcc DISP_CC_MDSS_BYTE0_INTF_CLK>,
					 <&dispcc DISP_CC_MDSS_PCLK0_CLK>,
					 <&dispcc DISP_CC_MDSS_ESC0_CLK>,
					 <&dispcc DISP_CC_MDSS_AHB_CLK>,
					 <&gcc GCC_DISP_HF_AXI_CLK>;
				clock-names = "byte",
					      "byte_intf",
					      "pixel",
					      "core",
					      "iface",
					      "bus";

				assigned-clocks = <&dispcc DISP_CC_MDSS_BYTE0_CLK_SRC>, <&dispcc DISP_CC_MDSS_PCLK0_CLK_SRC>;
				assigned-clock-parents = <&dsi_phy0 0>, <&dsi_phy0 1>;

				operating-points-v2 = <&dsi_opp_table>;
				power-domains = <&rpmpd SM6115_VDDMX>;

				phys = <&dsi_phy0>;
				phy-names = "dsi-phy";

				#address-cells = <1>;
				#size-cells = <0>;

				status = "disabled";

				ports {
					#address-cells = <1>;
					#size-cells = <0>;

					port@0 {
						reg = <0>;
						dsi0_in: endpoint {
							remote-endpoint = <&dpu_intf1_out>;
						};
					};

					port@1 {
						reg = <1>;
						dsi0_out: endpoint {
						};
					};
				};

				dsi_opp_table: dsi-opp-table {
					compatible = "operating-points-v2";

					opp-19200000 {
						opp-hz = /bits/ 64 <19200000>;
						required-opps = <&rpmpd_opp_nom>;
					};

					opp-164000000 {
						opp-hz = /bits/ 64 <164000000>;
						required-opps = <&rpmpd_opp_nom>;
					};

					opp-187500000 {
						opp-hz = /bits/ 64 <187500000>;
						required-opps = <&rpmpd_opp_nom>;
					};
				};
			};

			dsi_phy0: dsi-phy@5e94400 {
				compatible = "qcom,dsi-phy-14nm-6115";
				reg = <0x05e94400 0x100>,
				      <0x05e94500 0x300>,
				      <0x05e94800 0x188>;
				reg-names = "dsi_phy",
					    "dsi_phy_lane",
					    "dsi_pll";

				#clock-cells = <1>;
				#phy-cells = <0>;

				clocks = <&dispcc DISP_CC_MDSS_AHB_CLK>,
					 <&rpmcc RPM_SMD_XO_CLK_SRC>;
				clock-names = "iface", "ref";

				status = "disabled";
			};

		};

		rng: rng@1b53000 {
			compatible = "qcom,prng-ee";
			reg = <0x1b53000 0x1000>;
			clocks = <&gcc GCC_PRNG_AHB_CLK>;
			clock-names = "core";
		};
		
		spmi_bus: spmi@1c40000 {
			compatible = "qcom,spmi-pmic-arb";
			reg = <0x01c40000 0x1100>,
			      <0x01e00000 0x2000000>,
			      <0x03e00000 0x100000>,
			      <0x03f00000 0xa0000>,
			      <0x01c0a000 0x26000>;
			reg-names = "core", "chnls", "obsrvr", "intr", "cnfg";
			interrupt-names = "periph_irq";
			interrupts = <GIC_SPI 183 IRQ_TYPE_LEVEL_HIGH>;
			qcom,ee = <0>;
			qcom,channel = <0>;
			#address-cells = <2>;
			#size-cells = <0>;
			interrupt-controller;
			#interrupt-cells = <4>;
			cell-index = <0>;
		};
		
		apps_smmu: iommu@c600000 {
			compatible = "qcom,sm6115-smmu-500", "arm,mmu-500";
			reg = <0xc600000 0x80000>;
			#iommu-cells = <2>;
			#global-interrupts = <1>;

			status = "okay";
			interrupts =	<GIC_SPI 81 IRQ_TYPE_LEVEL_HIGH>,
					<GIC_SPI 88 IRQ_TYPE_LEVEL_HIGH>,
					<GIC_SPI 89 IRQ_TYPE_LEVEL_HIGH>,
					<GIC_SPI 90 IRQ_TYPE_LEVEL_HIGH>,
					<GIC_SPI 91 IRQ_TYPE_LEVEL_HIGH>,
					<GIC_SPI 92 IRQ_TYPE_LEVEL_HIGH>,
					<GIC_SPI 93 IRQ_TYPE_LEVEL_HIGH>,
					<GIC_SPI 94 IRQ_TYPE_LEVEL_HIGH>,
					<GIC_SPI 95 IRQ_TYPE_LEVEL_HIGH>,
					<GIC_SPI 96 IRQ_TYPE_LEVEL_HIGH>,
					<GIC_SPI 97 IRQ_TYPE_LEVEL_HIGH>,
					<GIC_SPI 98 IRQ_TYPE_LEVEL_HIGH>,
					<GIC_SPI 99 IRQ_TYPE_LEVEL_HIGH>,
					<GIC_SPI 100 IRQ_TYPE_LEVEL_HIGH>,
					<GIC_SPI 101 IRQ_TYPE_LEVEL_HIGH>,
					<GIC_SPI 102 IRQ_TYPE_LEVEL_HIGH>,
					<GIC_SPI 103 IRQ_TYPE_LEVEL_HIGH>,
					<GIC_SPI 104 IRQ_TYPE_LEVEL_HIGH>,
					<GIC_SPI 105 IRQ_TYPE_LEVEL_HIGH>,
					<GIC_SPI 106 IRQ_TYPE_LEVEL_HIGH>,
					<GIC_SPI 107 IRQ_TYPE_LEVEL_HIGH>,
					<GIC_SPI 108 IRQ_TYPE_LEVEL_HIGH>,
					<GIC_SPI 109 IRQ_TYPE_LEVEL_HIGH>,
					<GIC_SPI 110 IRQ_TYPE_LEVEL_HIGH>,
					<GIC_SPI 111 IRQ_TYPE_LEVEL_HIGH>,
					<GIC_SPI 112 IRQ_TYPE_LEVEL_HIGH>,
					<GIC_SPI 113 IRQ_TYPE_LEVEL_HIGH>,
					<GIC_SPI 114 IRQ_TYPE_LEVEL_HIGH>,
					<GIC_SPI 115 IRQ_TYPE_LEVEL_HIGH>,
					<GIC_SPI 116 IRQ_TYPE_LEVEL_HIGH>,
					<GIC_SPI 117 IRQ_TYPE_LEVEL_HIGH>,
					<GIC_SPI 118 IRQ_TYPE_LEVEL_HIGH>,
					<GIC_SPI 119 IRQ_TYPE_LEVEL_HIGH>,
					<GIC_SPI 120 IRQ_TYPE_LEVEL_HIGH>,
					<GIC_SPI 121 IRQ_TYPE_LEVEL_HIGH>,
					<GIC_SPI 122 IRQ_TYPE_LEVEL_HIGH>,
					<GIC_SPI 123 IRQ_TYPE_LEVEL_HIGH>,
					<GIC_SPI 124 IRQ_TYPE_LEVEL_HIGH>,
					<GIC_SPI 125 IRQ_TYPE_LEVEL_HIGH>,
					<GIC_SPI 126 IRQ_TYPE_LEVEL_HIGH>,
					<GIC_SPI 127 IRQ_TYPE_LEVEL_HIGH>,
					<GIC_SPI 128 IRQ_TYPE_LEVEL_HIGH>,
					<GIC_SPI 129 IRQ_TYPE_LEVEL_HIGH>,
					<GIC_SPI 130 IRQ_TYPE_LEVEL_HIGH>,
					<GIC_SPI 131 IRQ_TYPE_LEVEL_HIGH>,
					<GIC_SPI 132 IRQ_TYPE_LEVEL_HIGH>,
					<GIC_SPI 133 IRQ_TYPE_LEVEL_HIGH>,
					<GIC_SPI 134 IRQ_TYPE_LEVEL_HIGH>,
					<GIC_SPI 135 IRQ_TYPE_LEVEL_HIGH>,
					<GIC_SPI 136 IRQ_TYPE_LEVEL_HIGH>,
					<GIC_SPI 137 IRQ_TYPE_LEVEL_HIGH>,
					<GIC_SPI 138 IRQ_TYPE_LEVEL_HIGH>,
					<GIC_SPI 139 IRQ_TYPE_LEVEL_HIGH>,
					<GIC_SPI 140 IRQ_TYPE_LEVEL_HIGH>,
					<GIC_SPI 141 IRQ_TYPE_LEVEL_HIGH>,
					<GIC_SPI 142 IRQ_TYPE_LEVEL_HIGH>,
					<GIC_SPI 143 IRQ_TYPE_LEVEL_HIGH>,
					<GIC_SPI 144 IRQ_TYPE_LEVEL_HIGH>,
					<GIC_SPI 145 IRQ_TYPE_LEVEL_HIGH>,
					<GIC_SPI 146 IRQ_TYPE_LEVEL_HIGH>,
					<GIC_SPI 147 IRQ_TYPE_LEVEL_HIGH>,
					<GIC_SPI 148 IRQ_TYPE_LEVEL_HIGH>,
					<GIC_SPI 149 IRQ_TYPE_LEVEL_HIGH>,
					<GIC_SPI 150 IRQ_TYPE_LEVEL_HIGH>,
					<GIC_SPI 151 IRQ_TYPE_LEVEL_HIGH>;
		};


		apcs_glb: mailbox@f111000 {
			compatible = "qcom,sm6115-apcs-hmss-global";
			reg = <0x0f111000 0x1000>;

			#mbox-cells = <1>;
		};

		timer@f120000 {
			compatible = "arm,armv7-timer-mem";
			#address-cells = <1>;
			#size-cells = <1>;
			ranges;
			reg = < 0xf120000 0x1000>;
			clock-frequency = <19200000>;

			frame@f121000 {
				frame-number = <0>;
				interrupts = <GIC_SPI 8 IRQ_TYPE_LEVEL_HIGH>,
					     <GIC_SPI 7 IRQ_TYPE_LEVEL_HIGH>;
				reg = <0x0f121000 0x1000>,
				      <0x0f122000 0x1000>;
			};

			frame@f123000 {
				frame-number = <1>;
				interrupts = <GIC_SPI 9 IRQ_TYPE_LEVEL_HIGH>;
				reg = <0x0f123000 0x1000>;
				status = "disabled";
			};

			frame@f124000 {
				frame-number = <2>;
				interrupts = <GIC_SPI 10 IRQ_TYPE_LEVEL_HIGH>;
				reg = <0x0f124000 0x1000>;
				status = "disabled";
			};

			frame@f125000 {
				frame-number = <3>;
				interrupts = <GIC_SPI 11 IRQ_TYPE_LEVEL_HIGH>;
				reg = <0x0f125000 0x1000>;
				status = "disabled";
			};

			frame@f126000 {
				frame-number = <4>;
				interrupts = <GIC_SPI 12 IRQ_TYPE_LEVEL_HIGH>;
				reg = <0x0f126000 0x1000>;
				status = "disabled";
			};

			frame@f127000 {
				frame-number = <5>;
				interrupts = <GIC_SPI 13 IRQ_TYPE_LEVEL_HIGH>;
				reg = <0x0f127000 0x1000>;
				status = "disabled";
			};

			frame@f128000 {
				frame-number = <6>;
				interrupts = <GIC_SPI 14 IRQ_TYPE_LEVEL_HIGH>;
				reg = <0x0f128000 0x1000>;
				status = "disabled";
			};
		};

		intc: interrupt-controller@f200000 {
			compatible = "arm,gic-v3";
			reg = <0x0f200000 0x20000>,
			      <0x0f300000 0x100000>;
			#interrupt-cells = <3>;
			interrupt-controller;
			interrupts = <GIC_PPI 9 IRQ_TYPE_LEVEL_HIGH>;
		};
	};

	timer {
		compatible = "arm,armv8-timer";
		interrupts = <GIC_PPI 1 0xf08
			      GIC_PPI 2 0xf08
			      GIC_PPI 3 0xf08
			      GIC_PPI 0 0xf08>;
		clock-frequency = <19200000>;
	};
};
